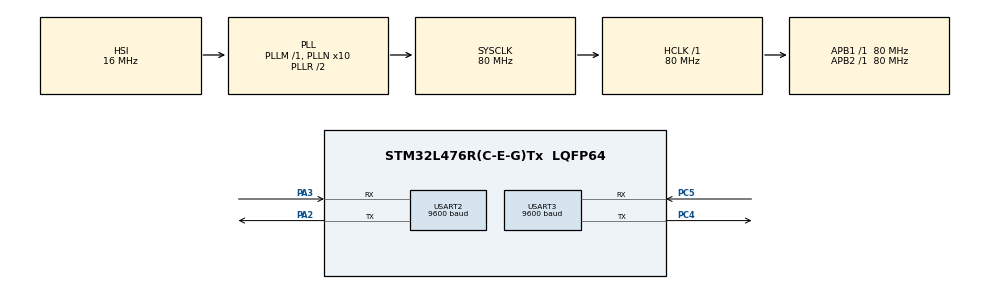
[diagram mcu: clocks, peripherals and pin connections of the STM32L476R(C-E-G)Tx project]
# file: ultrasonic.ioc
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Dma.Request0=USART2_RX
Dma.Request1=USART3_RX
Dma.USART2_RX.0.Direction=DMA_PERIPH_TO_MEMORY
Dma.USART2_RX.0.Instance=DMA1_Channel6
Dma.USART2_RX.0.MemDataAlignment=DMA_MDATAALIGN_BYTE
Dma.USART2_RX.0.MemInc=DMA_MINC_ENABLE
Dma.USART2_RX.0.Mode=DMA_CIRCULAR
Dma.USART2_RX.0.PeriphDataAlignment=DMA_PDATAALIGN_BYTE
Dma.USART2_RX.0.PeriphInc=DMA_PINC_DISABLE
Dma.USART2_RX.0.Priority=DMA_PRIORITY_LOW
Dma.USART3_RX.1.Direction=DMA_PERIPH_TO_MEMORY
Dma.USART3_RX.1.Instance=DMA1_Channel3
Dma.USART3_RX.1.MemDataAlignment=DMA_MDATAALIGN_BYTE
Dma.USART3_RX.1.MemInc=DMA_MINC_ENABLE
Dma.USART3_RX.1.Mode=DMA_CIRCULAR
Dma.USART3_RX.1.PeriphDataAlignment=DMA_PDATAALIGN_BYTE
Dma.USART3_RX.1.PeriphInc=DMA_PINC_DISABLE
Dma.USART3_RX.1.Priority=DMA_PRIORITY_LOW
Mcu.Family=STM32L4
Mcu.Name=STM32L476R(C-E-G)Tx
Mcu.Package=LQFP64
NVIC.DMA1_Channel3_IRQn=true\:0\:0\:false\:false\:true\:false\:true\:true
NVIC.DMA1_Channel6_IRQn=true\:0\:0\:false\:false\:true\:false\:true\:true
NVIC.PriorityGroup=NVIC_PRIORITYGROUP_4
NVIC.USART2_IRQn=true\:0\:0\:false\:false\:true\:true\:true\:true
NVIC.USART3_IRQn=true\:0\:0\:false\:false\:true\:true\:true\:true
PA13\ (JTMS-SWDIO).Mode=Serial_Wire
PA13\ (JTMS-SWDIO).Signal=SYS_JTMS-SWDIO
PA14\ (JTCK-SWCLK).Mode=Serial_Wire
PA14\ (JTCK-SWCLK).Signal=SYS_JTCK-SWCLK
PA2.Mode=Asynchronous
PA2.Signal=USART2_TX
PA3.Mode=Asynchronous
PA3.Signal=USART2_RX
PC4.Mode=Asynchronous
PC4.Signal=USART3_TX
PC5.Mode=Asynchronous
PC5.Signal=USART3_RX
PH0-OSC_IN\ (PH0).Mode=HSE-External-Oscillator
PH0-OSC_IN\ (PH0).Signal=RCC_OSC_IN
PH1-OSC_OUT\ (PH1).Mode=HSE-External-Oscillator
PH1-OSC_OUT\ (PH1).Signal=RCC_OSC_OUT
ProjectManager.HeapSize=0x200
ProjectManager.StackSize=0x400
ProjectManager.TargetToolchain=STM32CubeIDE
RCC.ADCFreq_Value=64000000
RCC.AHBFreq_Value=80000000
RCC.APB1Freq_Value=80000000
RCC.APB1TimFreq_Value=80000000
RCC.APB2Freq_Value=80000000
RCC.APB2TimFreq_Value=80000000
RCC.CortexFreq_Value=80000000
RCC.HCLKFreq_Value=80000000
RCC.HSE_VALUE=8000000
RCC.HSI_VALUE=16000000
RCC.LSE_VALUE=32768
RCC.MSI_VALUE=4000000
RCC.PLLN=10
RCC.PLLSourceVirtual=RCC_PLLSOURCE_HSI
RCC.SYSCLKFreq_VALUE=80000000
RCC.SYSCLKSource=RCC_SYSCLKSOURCE_PLLCLK
RCC.USBFreq_Value=64000000
RCC.VCOOutputFreq_Value=160000000
USART2.BaudRate=9600
USART2.VirtualMode-Asynchronous=VM_ASYNC
USART3.BaudRate=9600
USART3.VirtualMode-Asynchronous=VM_ASYNC
board=custom

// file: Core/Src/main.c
/* USER CODE BEGIN Header */
	/**
	 ******************************************************************************
	 * @file           : main.c
	 * @brief          : Main program body
	 ******************************************************************************
	 * @attention
	 *
	 * Copyright (c) 2022 STMicroelectronics.
	 * All rights reserved.
	 *
	 * This software is licensed under terms that can be found in the LICENSE file
	 * in the root directory of this software component.
	 * If no LICENSE file comes with this software, it is provided AS-IS.
	 *
	 ******************************************************************************
	 */
/* USER CODE END Header */
#include "main.h"

/* USER CODE BEGIN Includes */

#include "ultrasonic.h"
#include "string.h"
#include "stdio.h"
/* USER CODE END Includes */

UART_HandleTypeDef huart2;
UART_HandleTypeDef huart3;
DMA_HandleTypeDef hdma_usart2_rx;
DMA_HandleTypeDef hdma_usart3_rx;

/* USER CODE BEGIN PV */
uint16_t g_distance;
uint8_t Tx_Buf[50];
/* USER CODE END PV */

void SystemClock_Config(void);
static void MX_GPIO_Init(void);
static void MX_DMA_Init(void);
static void MX_USART2_UART_Init(void);
static void MX_USART3_UART_Init(void);

int main(void)
{

  /* MCU Configuration--------------------------------------------------------*/

  /* Reset of all peripherals, Initializes the Flash interface and the Systick. */
  HAL_Init();

  /* Configure the system clock */
  SystemClock_Config();

  /* Initialize all configured peripherals */
  MX_GPIO_Init();
  MX_DMA_Init();
  MX_USART2_UART_Init();
  MX_USART3_UART_Init();
  /* USER CODE BEGIN 2 */
	ultrasonic_init();
  /* USER CODE END 2 */

  /* Infinite loop */
  while (1)
  {

    /* USER CODE BEGIN 3 */
		if(g_dataReady_u8 == 1)
		{
			g_dataReady_u8 = 0;
			g_distance = Get_distance();
			uint8_t Len=sprintf(Tx_Buf,"DISTANCE: %d\r\n",g_distance);
			HAL_UART_Transmit(&huart2,(uint8_t *)Tx_Buf,Len,100);
			HAL_Delay(500);
		}
  }
  /* USER CODE END 3 */
}

void SystemClock_Config(void)
{
  RCC_OscInitTypeDef RCC_OscInitStruct = {0};
  RCC_ClkInitTypeDef RCC_ClkInitStruct = {0};

  /** Configure the main internal regulator output voltage
  */
  if (HAL_PWREx_ControlVoltageScaling(PWR_REGULATOR_VOLTAGE_SCALE1) != HAL_OK)
  {
    Error_Handler();
  }

  /** Initializes the RCC Oscillators according to the specified parameters
  * in the RCC_OscInitTypeDef structure.
  */
  RCC_OscInitStruct.OscillatorType = RCC_OSCILLATORTYPE_HSI;
  RCC_OscInitStruct.HSIState = RCC_HSI_ON;
  RCC_OscInitStruct.HSICalibrationValue = RCC_HSICALIBRATION_DEFAULT;
  RCC_OscInitStruct.PLL.PLLState = RCC_PLL_ON;
  RCC_OscInitStruct.PLL.PLLSource = RCC_PLLSOURCE_HSI;
  RCC_OscInitStruct.PLL.PLLM = 1;
  RCC_OscInitStruct.PLL.PLLN = 10;
  RCC_OscInitStruct.PLL.PLLP = RCC_PLLP_DIV7;
  RCC_OscInitStruct.PLL.PLLQ = RCC_PLLQ_DIV2;
  RCC_OscInitStruct.PLL.PLLR = RCC_PLLR_DIV2;
  if (HAL_RCC_OscConfig(&RCC_OscInitStruct) != HAL_OK)
  {
    Error_Handler();
  }

  /** Initializes the CPU, AHB and APB buses clocks
  */
  RCC_ClkInitStruct.ClockType = RCC_CLOCKTYPE_HCLK|RCC_CLOCKTYPE_SYSCLK
                              |RCC_CLOCKTYPE_PCLK1|RCC_CLOCKTYPE_PCLK2;
  RCC_ClkInitStruct.SYSCLKSource = RCC_SYSCLKSOURCE_PLLCLK;
  RCC_ClkInitStruct.AHBCLKDivider = RCC_SYSCLK_DIV1;
  RCC_ClkInitStruct.APB1CLKDivider = RCC_HCLK_DIV1;
  RCC_ClkInitStruct.APB2CLKDivider = RCC_HCLK_DIV1;

  if (HAL_RCC_ClockConfig(&RCC_ClkInitStruct, FLASH_LATENCY_4) != HAL_OK)
  {
    Error_Handler();
  }
}

static void MX_USART2_UART_Init(void)
{

  huart2.Instance = USART2;
  huart2.Init.BaudRate = 9600;
  huart2.Init.WordLength = UART_WORDLENGTH_8B;
  huart2.Init.StopBits = UART_STOPBITS_1;
  huart2.Init.Parity = UART_PARITY_NONE;
  huart2.Init.Mode = UART_MODE_TX_RX;
  huart2.Init.HwFlowCtl = UART_HWCONTROL_NONE;
  huart2.Init.OverSampling = UART_OVERSAMPLING_16;
  huart2.Init.OneBitSampling = UART_ONE_BIT_SAMPLE_DISABLE;
  huart2.AdvancedInit.AdvFeatureInit = UART_ADVFEATURE_NO_INIT;
  if (HAL_UART_Init(&huart2) != HAL_OK)
  {
    Error_Handler();
  }

}

static void MX_USART3_UART_Init(void)
{

  huart3.Instance = USART3;
  huart3.Init.BaudRate = 9600;
  huart3.Init.WordLength = UART_WORDLENGTH_8B;
  huart3.Init.StopBits = UART_STOPBITS_1;
  huart3.Init.Parity = UART_PARITY_NONE;
  huart3.Init.Mode = UART_MODE_TX_RX;
  huart3.Init.HwFlowCtl = UART_HWCONTROL_NONE;
  huart3.Init.OverSampling = UART_OVERSAMPLING_16;
  huart3.Init.OneBitSampling = UART_ONE_BIT_SAMPLE_DISABLE;
  huart3.AdvancedInit.AdvFeatureInit = UART_ADVFEATURE_NO_INIT;
  if (HAL_UART_Init(&huart3) != HAL_OK)
  {
    Error_Handler();
  }

}

static void MX_DMA_Init(void)
{

  /* DMA controller clock enable */
  __HAL_RCC_DMA1_CLK_ENABLE();

  /* DMA interrupt init */
  /* DMA1_Channel3_IRQn interrupt configuration */
  HAL_NVIC_SetPriority(DMA1_Channel3_IRQn, 0, 0);
  HAL_NVIC_EnableIRQ(DMA1_Channel3_IRQn);
  /* DMA1_Channel6_IRQn interrupt configuration */
  HAL_NVIC_SetPriority(DMA1_Channel6_IRQn, 0, 0);
  HAL_NVIC_EnableIRQ(DMA1_Channel6_IRQn);

}

static void MX_GPIO_Init(void)
{

  /* GPIO Ports Clock Enable */
  __HAL_RCC_GPIOH_CLK_ENABLE();
  __HAL_RCC_GPIOA_CLK_ENABLE();
  __HAL_RCC_GPIOC_CLK_ENABLE();

}

void Error_Handler(void)
{
		__disable_irq();
		while (1)
		{
		}
}
